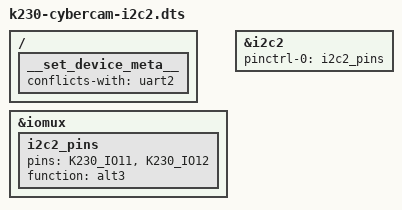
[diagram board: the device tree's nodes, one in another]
// SPDX-License-Identifier: GPL-2.0 OR MIT
/dts-v1/;
/plugin/;
#include <dt-bindings/pinctrl/canaan,k230-iomux.h>

/ {
	fragment@0 {
		target = <&iomux>;
		__overlay__ {
			i2c2_pins: i2c2_pins {
				pins = K230_IO11, K230_IO12;
				function = "alt3";
			};
		};
	};

	fragment@1 {
		target = <&i2c2>;
		__overlay__ {
			status = "okay";
			pinctrl-names = "default";
			pinctrl-0 = <&i2c2_pins>;
		};
	};
	__set_device_meta__ {
		conflicts-with = "uart2";
	};
};
